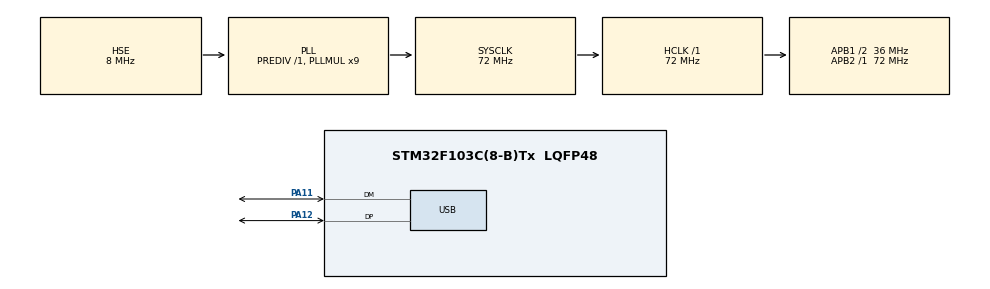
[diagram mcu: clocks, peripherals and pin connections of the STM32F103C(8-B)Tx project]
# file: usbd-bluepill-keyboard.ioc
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Mcu.Family=STM32F1
Mcu.Name=STM32F103C(8-B)Tx
Mcu.Package=LQFP48
NVIC.PriorityGroup=NVIC_PRIORITYGROUP_4
NVIC.USB_LP_CAN1_RX0_IRQn=true\:0\:0\:false\:false\:true\:false\:true\:true
PA11.Mode=Device
PA11.Signal=USB_DM
PA12.Mode=Device
PA12.Signal=USB_DP
PA13.Mode=Serial_Wire
PA13.Signal=SYS_JTMS-SWDIO
PA14.Mode=Serial_Wire
PA14.Signal=SYS_JTCK-SWCLK
PD0-OSC_IN.Mode=HSE-External-Oscillator
PD0-OSC_IN.Signal=RCC_OSC_IN
PD1-OSC_OUT.Mode=HSE-External-Oscillator
PD1-OSC_OUT.Signal=RCC_OSC_OUT
ProjectManager.HeapSize=0x200
ProjectManager.StackSize=0x400
ProjectManager.TargetToolchain=Makefile
RCC.AHBFreq_Value=72000000
RCC.APB1CLKDivider=RCC_HCLK_DIV2
RCC.APB1Freq_Value=36000000
RCC.APB1TimFreq_Value=72000000
RCC.APB2Freq_Value=72000000
RCC.APB2TimFreq_Value=72000000
RCC.HCLKFreq_Value=72000000
RCC.PLLMUL=RCC_PLL_MUL9
RCC.SYSCLKFreq_VALUE=72000000
RCC.SYSCLKSource=RCC_SYSCLKSOURCE_PLLCLK
RCC.USBFreq_Value=48000000
RCC.USBPrescaler=RCC_USBCLKSOURCE_PLL_DIV1_5
USB_DEVICE.CLASS_NAME_FS=HID
USB_DEVICE.PRODUCT_STRING_HID_FS=Knowledge Hub Keyboard
USB_DEVICE.VirtualMode=Hid
USB_DEVICE.VirtualModeFS=Hid_FS
VP_USB_DEVICE_VS_USB_DEVICE_HID_FS.Mode=HID_FS
board=custom

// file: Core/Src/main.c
/* USER CODE BEGIN Header */
/**
  ******************************************************************************
  * @file           : main.c
  * @brief          : Main program body
  ******************************************************************************
  * @attention
  *
  * <h2><center>&copy; Copyright (c) 2021 STMicroelectronics.
  * All rights reserved.</center></h2>
  *
  * This software component is licensed by ST under BSD 3-Clause license,
  * the "License"; You may not use this file except in compliance with the
  * License. You may obtain a copy of the License at:
  *                        opensource.org/licenses/BSD-3-Clause
  *
  ******************************************************************************
  */
/* USER CODE END Header */
#include "main.h"
#include "usb_device.h"
#include "gpio.h"

/* USER CODE BEGIN Includes */
#include "usbd_hid.h" // Подключаем библиотеку для работы с HID
#include <string.h>   // Подключаем для использования strlen()
/* USER CODE END Includes */

/* USER CODE BEGIN PTD */
// --- ИЗМЕНЕНИЕ 1: Добавляем структуру для HID отчета клавиатуры ---
typedef struct {
    uint8_t MODIFIER;
    uint8_t RESERVED;
    uint8_t KEYCODE[6];
} keyboard_report_t;
/* USER CODE END PTD */

/* USER CODE BEGIN PD */
#define KEY_F15 0x6A

#define SLEEP_DELAY_MS 10000 // 10 секунд нахождения в состоянии сна
#define WAKE_DELAY_MS  20000 // 20 секунд нахождения в активном состоянии
/* USER CODE END PD */

/* USER CODE BEGIN PV */
extern USBD_HandleTypeDef hUsbDeviceFS;
keyboard_report_t keyboard_report;
/* USER CODE END PV */

void SystemClock_Config(void);
/* USER CODE BEGIN PFP */
void Send_HID_Keyboard(uint8_t key_code, uint8_t modifier);
/* USER CODE END PFP */

int main(void)
{

  /* MCU Configuration--------------------------------------------------------*/

  /* Reset of all peripherals, Initializes the Flash interface and the Systick. */
  HAL_Init();

  /* Configure the system clock */
  SystemClock_Config();

  /* Initialize all configured peripherals */
  MX_GPIO_Init();
  MX_USB_DEVICE_Init();
  /* USER CODE BEGIN 2 */
  // Даем небольшую паузу, чтобы USB успел инициализироваться на хосте
  HAL_Delay(2000);

  // Инициализируем структуру отчета нулями
  memset(&keyboard_report, 0, sizeof(keyboard_report));
  /* USER CODE END 2 */

  /* Infinite loop */
  while (1)
  {

    /* USER CODE BEGIN 3 */
    // Отправляем нажатие клавиши F15 (код 0x68) без модификаторов (0x00)
    //Send_HID_Keyboard(0x68, 0x00);
    //Send_HID_Keyboard(0x04, 0x02); // Отправляем 'A' с Left Shift (чтобы получить заглавную букву)
    // Отправляем нажатие клавиши F15 (код 0x68) без модификаторов (0x00)
    Send_HID_Keyboard(0x04, 0x02);

    HAL_Delay(5000); // Пауза 5 секунд
  }
  /* USER CODE END 3 */
}

void SystemClock_Config(void)
{
  RCC_OscInitTypeDef RCC_OscInitStruct = {0};
  RCC_ClkInitTypeDef RCC_ClkInitStruct = {0};
  RCC_PeriphCLKInitTypeDef PeriphClkInit = {0};

  /** Initializes the RCC Oscillators according to the specified parameters
  * in the RCC_OscInitTypeDef structure.
  */
  RCC_OscInitStruct.OscillatorType = RCC_OSCILLATORTYPE_HSE;
  RCC_OscInitStruct.HSEState = RCC_HSE_ON;
  RCC_OscInitStruct.HSEPredivValue = RCC_HSE_PREDIV_DIV1;
  RCC_OscInitStruct.HSIState = RCC_HSI_ON;
  RCC_OscInitStruct.PLL.PLLState = RCC_PLL_ON;
  RCC_OscInitStruct.PLL.PLLSource = RCC_PLLSOURCE_HSE;
  RCC_OscInitStruct.PLL.PLLMUL = RCC_PLL_MUL9;
  if (HAL_RCC_OscConfig(&RCC_OscInitStruct) != HAL_OK)
  {
    Error_Handler();
  }

  /** Initializes the CPU, AHB and APB buses clocks
  */
  RCC_ClkInitStruct.ClockType = RCC_CLOCKTYPE_HCLK|RCC_CLOCKTYPE_SYSCLK
                              |RCC_CLOCKTYPE_PCLK1|RCC_CLOCKTYPE_PCLK2;
  RCC_ClkInitStruct.SYSCLKSource = RCC_SYSCLKSOURCE_PLLCLK;
  RCC_ClkInitStruct.AHBCLKDivider = RCC_SYSCLK_DIV1;
  RCC_ClkInitStruct.APB1CLKDivider = RCC_HCLK_DIV2;
  RCC_ClkInitStruct.APB2CLKDivider = RCC_HCLK_DIV1;

  if (HAL_RCC_ClockConfig(&RCC_ClkInitStruct, FLASH_LATENCY_2) != HAL_OK)
  {
    Error_Handler();
  }
  PeriphClkInit.PeriphClockSelection = RCC_PERIPHCLK_USB;
  PeriphClkInit.UsbClockSelection = RCC_USBCLKSOURCE_PLL_DIV1_5;
  if (HAL_RCCEx_PeriphCLKConfig(&PeriphClkInit) != HAL_OK)
  {
    Error_Handler();
  }
}

/* USER CODE BEGIN 4 */

void Send_HID_Keyboard(uint8_t key_code, uint8_t modifier)
{
    // Нажатие
    keyboard_report.MODIFIER = modifier;
    keyboard_report.RESERVED = 0;
    keyboard_report.KEYCODE[0] = key_code;
    for (int i = 1; i < 6; i++) {
        keyboard_report.KEYCODE[i] = 0;
    }

    USBD_HID_SendReport(&hUsbDeviceFS, (uint8_t*)&keyboard_report, sizeof(keyboard_report));
    HAL_Delay(50);

    // Отпускание
    keyboard_report.MODIFIER = 0;
    for (int i = 0; i < 6; i++) {
        keyboard_report.KEYCODE[i] = 0;
    }

    USBD_HID_SendReport(&hUsbDeviceFS, (uint8_t*)&keyboard_report, sizeof(keyboard_report));
    HAL_Delay(20);
}

/* USER CODE END 4 */

void Error_Handler(void)
{
  __disable_irq();
  while (1)
  {
  }
}
